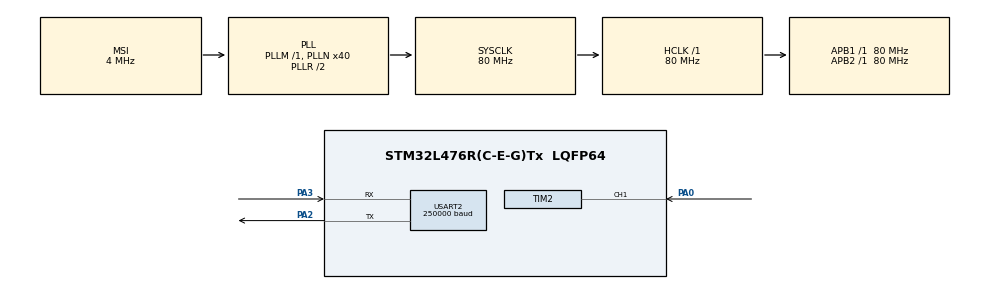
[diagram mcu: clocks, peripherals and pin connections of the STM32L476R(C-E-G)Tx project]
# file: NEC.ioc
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Mcu.Family=STM32L4
Mcu.Name=STM32L476R(C-E-G)Tx
Mcu.Package=LQFP64
NVIC.PriorityGroup=NVIC_PRIORITYGROUP_4
NVIC.TIM2_IRQn=true\:5\:0\:true\:false\:true\:true\:true\:true
PA0.Signal=S_TIM2_CH1
PA2.Mode=Asynchronous
PA2.Signal=USART2_TX
PA3.Mode=Asynchronous
PA3.Signal=USART2_RX
ProjectManager.HeapSize=0x200
ProjectManager.StackSize=0x400
ProjectManager.TargetToolchain=STM32CubeIDE
RCC.AHBFreq_Value=80000000
RCC.APB1Freq_Value=80000000
RCC.APB1TimFreq_Value=80000000
RCC.APB2Freq_Value=80000000
RCC.APB2TimFreq_Value=80000000
RCC.CortexFreq_Value=80000000
RCC.HCLKFreq_Value=80000000
RCC.HSE_VALUE=8000000
RCC.HSI_VALUE=16000000
RCC.LSE_VALUE=32768
RCC.MSI_VALUE=4000000
RCC.PLLN=40
RCC.SYSCLKFreq_VALUE=80000000
RCC.SYSCLKSource=RCC_SYSCLKSOURCE_PLLCLK
RCC.VCOOutputFreq_Value=160000000
SH.S_TIM2_CH1.0=TIM2_CH1,TriggerSource_TI1ED
SH.S_TIM2_CH1.1=TIM2_CH1,Input_Capture1_from_TI1
TIM2.Channel-Input_Capture1_from_TI1=TIM_CHANNEL_1
TIM2.ICPolarity_CH1=TIM_INPUTCHANNELPOLARITY_FALLING
TIM2.Prescaler=79
USART2.BaudRate=250000
USART2.VirtualMode-Asynchronous=VM_ASYNC
VP_TIM2_VS_ClockSourceINT.Mode=Internal
VP_TIM2_VS_ControllerModeReset.Mode=Reset Mode
board=custom

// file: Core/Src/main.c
/* USER CODE BEGIN Header */
/*
 * main.c
 * Program read values from IR sensor
 *  Created on: Feb 16, 2023
 *      Author: kduljas
 */
/* USER CODE END Header */
#include "main.h"
#include "tim.h"
#include "usart.h"
#include "gpio.h"

/* USER CODE BEGIN Includes */
#include "ioputchar.h"
#include "ir.h"
#include "stdio.h"
/* USER CODE END Includes */

void SystemClock_Config(void);

/* USER CODE BEGIN 0 */
void HAL_TIM_IC_CaptureCallback(TIM_HandleTypeDef *htim)
{
  if (htim == &htim2) {
    switch (HAL_TIM_GetActiveChannel(&htim2)) {
      case HAL_TIM_ACTIVE_CHANNEL_1:
    	  ir_tim_interrupt();

        //__BKPT(0);
        break;
      default:
        break;
    }
  }
}
/* USER CODE END 0 */

int main(void)
{

  /* MCU Configuration--------------------------------------------------------*/

  /* Reset of all peripherals, Initializes the Flash interface and the Systick. */
  HAL_Init();

  /* Configure the system clock */
  SystemClock_Config();

  /* Initialize all configured peripherals */
  MX_GPIO_Init();
  MX_TIM2_Init();
  MX_USART2_UART_Init();
  /* USER CODE BEGIN 2 */
  HAL_TIM_Base_Start(&htim2);
  HAL_TIM_IC_Start_IT(&htim2, TIM_CHANNEL_1);
  /* USER CODE END 2 */

  /* Infinite loop */
  /* USER CODE BEGIN WHILE */
  printf("Hello\n");
  while (1)
  {
    /* USER CODE END WHILE */

    /* USER CODE BEGIN 3 */
	int value = ir_read();
    if (value != -1) {
      printf("code = %02x\n", value);
    }

  }
  /* USER CODE END 3 */
}

void SystemClock_Config(void)
{
  RCC_OscInitTypeDef RCC_OscInitStruct = {0};
  RCC_ClkInitTypeDef RCC_ClkInitStruct = {0};

  /** Configure the main internal regulator output voltage
  */
  if (HAL_PWREx_ControlVoltageScaling(PWR_REGULATOR_VOLTAGE_SCALE1) != HAL_OK)
  {
    Error_Handler();
  }

  /** Initializes the RCC Oscillators according to the specified parameters
  * in the RCC_OscInitTypeDef structure.
  */
  RCC_OscInitStruct.OscillatorType = RCC_OSCILLATORTYPE_MSI;
  RCC_OscInitStruct.MSIState = RCC_MSI_ON;
  RCC_OscInitStruct.MSICalibrationValue = 0;
  RCC_OscInitStruct.MSIClockRange = RCC_MSIRANGE_6;
  RCC_OscInitStruct.PLL.PLLState = RCC_PLL_ON;
  RCC_OscInitStruct.PLL.PLLSource = RCC_PLLSOURCE_MSI;
  RCC_OscInitStruct.PLL.PLLM = 1;
  RCC_OscInitStruct.PLL.PLLN = 40;
  RCC_OscInitStruct.PLL.PLLP = RCC_PLLP_DIV7;
  RCC_OscInitStruct.PLL.PLLQ = RCC_PLLQ_DIV2;
  RCC_OscInitStruct.PLL.PLLR = RCC_PLLR_DIV2;
  if (HAL_RCC_OscConfig(&RCC_OscInitStruct) != HAL_OK)
  {
    Error_Handler();
  }

  /** Initializes the CPU, AHB and APB buses clocks
  */
  RCC_ClkInitStruct.ClockType = RCC_CLOCKTYPE_HCLK|RCC_CLOCKTYPE_SYSCLK
                              |RCC_CLOCKTYPE_PCLK1|RCC_CLOCKTYPE_PCLK2;
  RCC_ClkInitStruct.SYSCLKSource = RCC_SYSCLKSOURCE_PLLCLK;
  RCC_ClkInitStruct.AHBCLKDivider = RCC_SYSCLK_DIV1;
  RCC_ClkInitStruct.APB1CLKDivider = RCC_HCLK_DIV1;
  RCC_ClkInitStruct.APB2CLKDivider = RCC_HCLK_DIV1;

  if (HAL_RCC_ClockConfig(&RCC_ClkInitStruct, FLASH_LATENCY_4) != HAL_OK)
  {
    Error_Handler();
  }
}

void Error_Handler(void)
{
  __disable_irq();
  while (1)
  {
  }
}
